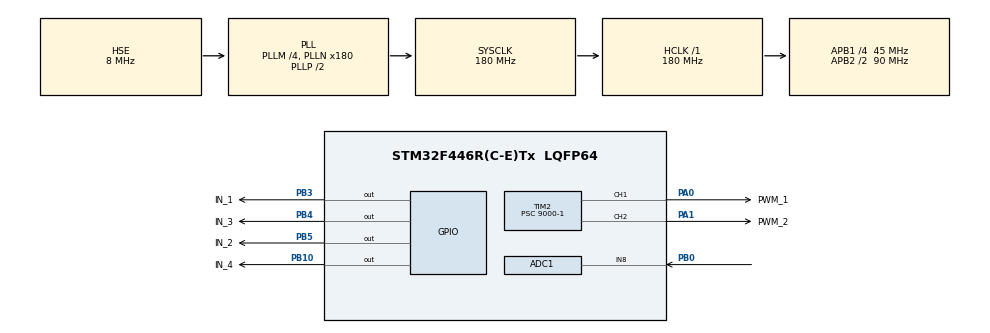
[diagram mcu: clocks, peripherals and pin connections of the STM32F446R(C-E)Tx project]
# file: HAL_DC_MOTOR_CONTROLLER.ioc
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ADC1.Channel-0\#ChannelRegularConversion=ADC_CHANNEL_8
ADC1.ContinuousConvMode=ENABLE
ADC1.DMAContinuousRequests=DISABLE
ADC1.NbrOfConversionFlag=1
ADC1.Rank-0\#ChannelRegularConversion=1
ADC1.Resolution=ADC_RESOLUTION_10B
ADC1.SamplingTime-0\#ChannelRegularConversion=ADC_SAMPLETIME_84CYCLES
ADC1.master=1
Mcu.Family=STM32F4
Mcu.Name=STM32F446R(C-E)Tx
Mcu.Package=LQFP64
NVIC.ADC_IRQn=true\:0\:0\:false\:false\:true\:true\:true
NVIC.PriorityGroup=NVIC_PRIORITYGROUP_4
PA0-WKUP.GPIO_Label=PWM_1
PA0-WKUP.Signal=S_TIM2_CH1_ETR
PA1.GPIO_Label=PWM_2
PA1.Signal=S_TIM2_CH2
PB0.Signal=ADCx_IN8
PB10.GPIO_Label=IN_4
PB10.Signal=GPIO_Output
PB3.GPIO_Label=IN_1
PB3.Signal=GPIO_Output
PB4.GPIO_Label=IN_3
PB4.Signal=GPIO_Output
PB5.GPIO_Label=IN_2
PB5.Signal=GPIO_Output
PH0-OSC_IN.Mode=HSE-External-Oscillator
PH0-OSC_IN.Signal=RCC_OSC_IN
PH1-OSC_OUT.Mode=HSE-External-Oscillator
PH1-OSC_OUT.Signal=RCC_OSC_OUT
ProjectManager.HeapSize=0x200
ProjectManager.StackSize=0x400
ProjectManager.TargetToolchain=STM32CubeIDE
RCC.AHBFreq_Value=180000000
RCC.APB1CLKDivider=RCC_HCLK_DIV4
RCC.APB1Freq_Value=45000000
RCC.APB1TimFreq_Value=90000000
RCC.APB2CLKDivider=RCC_HCLK_DIV2
RCC.APB2Freq_Value=90000000
RCC.APB2TimFreq_Value=180000000
RCC.CortexFreq_Value=180000000
RCC.HCLKFreq_Value=180000000
RCC.HSE_VALUE=8000000
RCC.PLLM=4
RCC.PLLN=180
RCC.PLLSourceVirtual=RCC_PLLSOURCE_HSE
RCC.SYSCLKFreq_VALUE=180000000
RCC.SYSCLKSource=RCC_SYSCLKSOURCE_PLLCLK
RCC.USBFreq_Value=180000000
RCC.VCOOutputFreq_Value=360000000
SH.ADCx_IN8.0=ADC1_IN8,IN8
SH.S_TIM2_CH1_ETR.0=TIM2_CH1,PWM Generation1 CH1
SH.S_TIM2_CH2.0=TIM2_CH2,PWM Generation2 CH2
TIM2.Channel-PWM\ Generation1\ CH1=TIM_CHANNEL_1
TIM2.Channel-PWM\ Generation2\ CH2=TIM_CHANNEL_2
TIM2.Period=1024-1
TIM2.Prescaler=9000-1
TIM2.Pulse-PWM\ Generation1\ CH1=600
VP_TIM2_VS_ClockSourceINT.Mode=Internal
board=custom

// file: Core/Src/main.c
/* USER CODE BEGIN Header */
/**
  ******************************************************************************
  * @file           : main.c
  * @brief          : Main program body
  ******************************************************************************
  * @attention
  *
  * <h2><center>&copy; Copyright (c) 2020 STMicroelectronics.
  * All rights reserved.</center></h2>
  *
  * This software component is licensed by ST under BSD 3-Clause license,
  * the "License"; You may not use this file except in compliance with the
  * License. You may obtain a copy of the License at:
  *                        opensource.org/licenses/BSD-3-Clause
  *
  ******************************************************************************
  */
/* USER CODE END Header */
#include "main.h"

ADC_HandleTypeDef hadc1;

TIM_HandleTypeDef htim2;

/* USER CODE BEGIN PV */
volatile uint16_t pwm;
/* USER CODE END PV */

void SystemClock_Config(void);
static void MX_GPIO_Init(void);
static void MX_TIM2_Init(void);
static void MX_ADC1_Init(void);

/* USER CODE BEGIN 0 */

void HAL_ADC_ConvCpltCallback(ADC_HandleTypeDef* hadc)
{
	 pwm=HAL_ADC_GetValue(&hadc1);
	 __HAL_TIM_SET_COMPARE(&htim2,TIM_CHANNEL_1,pwm);
	 __HAL_TIM_SET_COMPARE(&htim2,TIM_CHANNEL_2,pwm);
}

/* USER CODE END 0 */

int main(void)
{

  /* MCU Configuration--------------------------------------------------------*/

  /* Reset of all peripherals, Initializes the Flash interface and the Systick. */
  HAL_Init();

  /* Configure the system clock */
  SystemClock_Config();

  /* Initialize all configured peripherals */
  MX_GPIO_Init();
  MX_TIM2_Init();
  MX_ADC1_Init();
  /* USER CODE BEGIN 2 */
  HAL_ADC_Start_IT(&hadc1);
  HAL_TIM_PWM_Start(&htim2, TIM_CHANNEL_1);
  HAL_TIM_PWM_Start(&htim2, TIM_CHANNEL_2);
/*  __HAL_TIM_SET_COMPARE(&htim2,TIM_CHANNEL_1,1023);
  __HAL_TIM_SET_COMPARE(&htim2,TIM_CHANNEL_2,1023);*/
  HAL_GPIO_WritePin(IN_1_GPIO_Port, IN_1_Pin, GPIO_PIN_SET);
  HAL_GPIO_WritePin(IN_2_GPIO_Port, IN_2_Pin, GPIO_PIN_RESET);
  HAL_GPIO_WritePin(IN_3_GPIO_Port, IN_3_Pin, GPIO_PIN_SET);
  HAL_GPIO_WritePin(IN_4_GPIO_Port, IN_4_Pin, GPIO_PIN_RESET);
  /* USER CODE END 2 */

  /* Infinite loop */
  /* USER CODE BEGIN WHILE */
  while (1)
  {
/*	  __HAL_TIM_SET_COMPARE(&htim2,TIM_CHANNEL_1,500);
	  HAL_Delay(100);
	  __HAL_TIM_SET_COMPARE(&htim2,TIM_CHANNEL_1,800);
	  HAL_Delay(300);*/

    /* USER CODE END WHILE */

  }
}

void SystemClock_Config(void)
{
  RCC_OscInitTypeDef RCC_OscInitStruct = {0};
  RCC_ClkInitTypeDef RCC_ClkInitStruct = {0};

  /** Configure the main internal regulator output voltage
  */
  __HAL_RCC_PWR_CLK_ENABLE();
  __HAL_PWR_VOLTAGESCALING_CONFIG(PWR_REGULATOR_VOLTAGE_SCALE1);
  /** Initializes the RCC Oscillators according to the specified parameters
  * in the RCC_OscInitTypeDef structure.
  */
  RCC_OscInitStruct.OscillatorType = RCC_OSCILLATORTYPE_HSE;
  RCC_OscInitStruct.HSEState = RCC_HSE_ON;
  RCC_OscInitStruct.PLL.PLLState = RCC_PLL_ON;
  RCC_OscInitStruct.PLL.PLLSource = RCC_PLLSOURCE_HSE;
  RCC_OscInitStruct.PLL.PLLM = 4;
  RCC_OscInitStruct.PLL.PLLN = 180;
  RCC_OscInitStruct.PLL.PLLP = RCC_PLLP_DIV2;
  RCC_OscInitStruct.PLL.PLLQ = 2;
  RCC_OscInitStruct.PLL.PLLR = 2;
  if (HAL_RCC_OscConfig(&RCC_OscInitStruct) != HAL_OK)
  {
    Error_Handler();
  }
  /** Activate the Over-Drive mode
  */
  if (HAL_PWREx_EnableOverDrive() != HAL_OK)
  {
    Error_Handler();
  }
  /** Initializes the CPU, AHB and APB buses clocks
  */
  RCC_ClkInitStruct.ClockType = RCC_CLOCKTYPE_HCLK|RCC_CLOCKTYPE_SYSCLK
                              |RCC_CLOCKTYPE_PCLK1|RCC_CLOCKTYPE_PCLK2;
  RCC_ClkInitStruct.SYSCLKSource = RCC_SYSCLKSOURCE_PLLCLK;
  RCC_ClkInitStruct.AHBCLKDivider = RCC_SYSCLK_DIV1;
  RCC_ClkInitStruct.APB1CLKDivider = RCC_HCLK_DIV4;
  RCC_ClkInitStruct.APB2CLKDivider = RCC_HCLK_DIV2;

  if (HAL_RCC_ClockConfig(&RCC_ClkInitStruct, FLASH_LATENCY_5) != HAL_OK)
  {
    Error_Handler();
  }
}

static void MX_ADC1_Init(void)
{

  ADC_ChannelConfTypeDef sConfig = {0};

  /** Configure the global features of the ADC (Clock, Resolution, Data Alignment and number of conversion)
  */
  hadc1.Instance = ADC1;
  hadc1.Init.ClockPrescaler = ADC_CLOCK_SYNC_PCLK_DIV4;
  hadc1.Init.Resolution = ADC_RESOLUTION_10B;
  hadc1.Init.ScanConvMode = DISABLE;
  hadc1.Init.ContinuousConvMode = ENABLE;
  hadc1.Init.DiscontinuousConvMode = DISABLE;
  hadc1.Init.ExternalTrigConvEdge = ADC_EXTERNALTRIGCONVEDGE_NONE;
  hadc1.Init.ExternalTrigConv = ADC_SOFTWARE_START;
  hadc1.Init.DataAlign = ADC_DATAALIGN_RIGHT;
  hadc1.Init.NbrOfConversion = 1;
  hadc1.Init.DMAContinuousRequests = DISABLE;
  hadc1.Init.EOCSelection = ADC_EOC_SINGLE_CONV;
  if (HAL_ADC_Init(&hadc1) != HAL_OK)
  {
    Error_Handler();
  }
  /** Configure for the selected ADC regular channel its corresponding rank in the sequencer and its sample time.
  */
  sConfig.Channel = ADC_CHANNEL_8;
  sConfig.Rank = 1;
  sConfig.SamplingTime = ADC_SAMPLETIME_84CYCLES;
  if (HAL_ADC_ConfigChannel(&hadc1, &sConfig) != HAL_OK)
  {
    Error_Handler();
  }

}

static void MX_TIM2_Init(void)
{

  TIM_ClockConfigTypeDef sClockSourceConfig = {0};
  TIM_MasterConfigTypeDef sMasterConfig = {0};
  TIM_OC_InitTypeDef sConfigOC = {0};

  htim2.Instance = TIM2;
  htim2.Init.Prescaler = 9000-1;
  htim2.Init.CounterMode = TIM_COUNTERMODE_UP;
  htim2.Init.Period = 1024-1;
  htim2.Init.ClockDivision = TIM_CLOCKDIVISION_DIV1;
  htim2.Init.AutoReloadPreload = TIM_AUTORELOAD_PRELOAD_DISABLE;
  if (HAL_TIM_Base_Init(&htim2) != HAL_OK)
  {
    Error_Handler();
  }
  sClockSourceConfig.ClockSource = TIM_CLOCKSOURCE_INTERNAL;
  if (HAL_TIM_ConfigClockSource(&htim2, &sClockSourceConfig) != HAL_OK)
  {
    Error_Handler();
  }
  if (HAL_TIM_PWM_Init(&htim2) != HAL_OK)
  {
    Error_Handler();
  }
  sMasterConfig.MasterOutputTrigger = TIM_TRGO_RESET;
  sMasterConfig.MasterSlaveMode = TIM_MASTERSLAVEMODE_DISABLE;
  if (HAL_TIMEx_MasterConfigSynchronization(&htim2, &sMasterConfig) != HAL_OK)
  {
    Error_Handler();
  }
  sConfigOC.OCMode = TIM_OCMODE_PWM1;
  sConfigOC.Pulse = 600;
  sConfigOC.OCPolarity = TIM_OCPOLARITY_HIGH;
  sConfigOC.OCFastMode = TIM_OCFAST_DISABLE;
  if (HAL_TIM_PWM_ConfigChannel(&htim2, &sConfigOC, TIM_CHANNEL_1) != HAL_OK)
  {
    Error_Handler();
  }
  sConfigOC.Pulse = 0;
  if (HAL_TIM_PWM_ConfigChannel(&htim2, &sConfigOC, TIM_CHANNEL_2) != HAL_OK)
  {
    Error_Handler();
  }
  HAL_TIM_MspPostInit(&htim2);

}

static void MX_GPIO_Init(void)
{
  GPIO_InitTypeDef GPIO_InitStruct = {0};

  /* GPIO Ports Clock Enable */
  __HAL_RCC_GPIOH_CLK_ENABLE();
  __HAL_RCC_GPIOA_CLK_ENABLE();
  __HAL_RCC_GPIOB_CLK_ENABLE();

  /*Configure GPIO pin Output Level */
  HAL_GPIO_WritePin(GPIOB, IN_4_Pin|IN_1_Pin|IN_3_Pin|IN_2_Pin, GPIO_PIN_RESET);

  /*Configure GPIO pins : IN_4_Pin IN_1_Pin IN_3_Pin IN_2_Pin */
  GPIO_InitStruct.Pin = IN_4_Pin|IN_1_Pin|IN_3_Pin|IN_2_Pin;
  GPIO_InitStruct.Mode = GPIO_MODE_OUTPUT_PP;
  GPIO_InitStruct.Pull = GPIO_NOPULL;
  GPIO_InitStruct.Speed = GPIO_SPEED_FREQ_LOW;
  HAL_GPIO_Init(GPIOB, &GPIO_InitStruct);

}

void Error_Handler(void)
{
}

/************************ (C) COPYRIGHT STMicroelectronics *****END OF FILE****/
